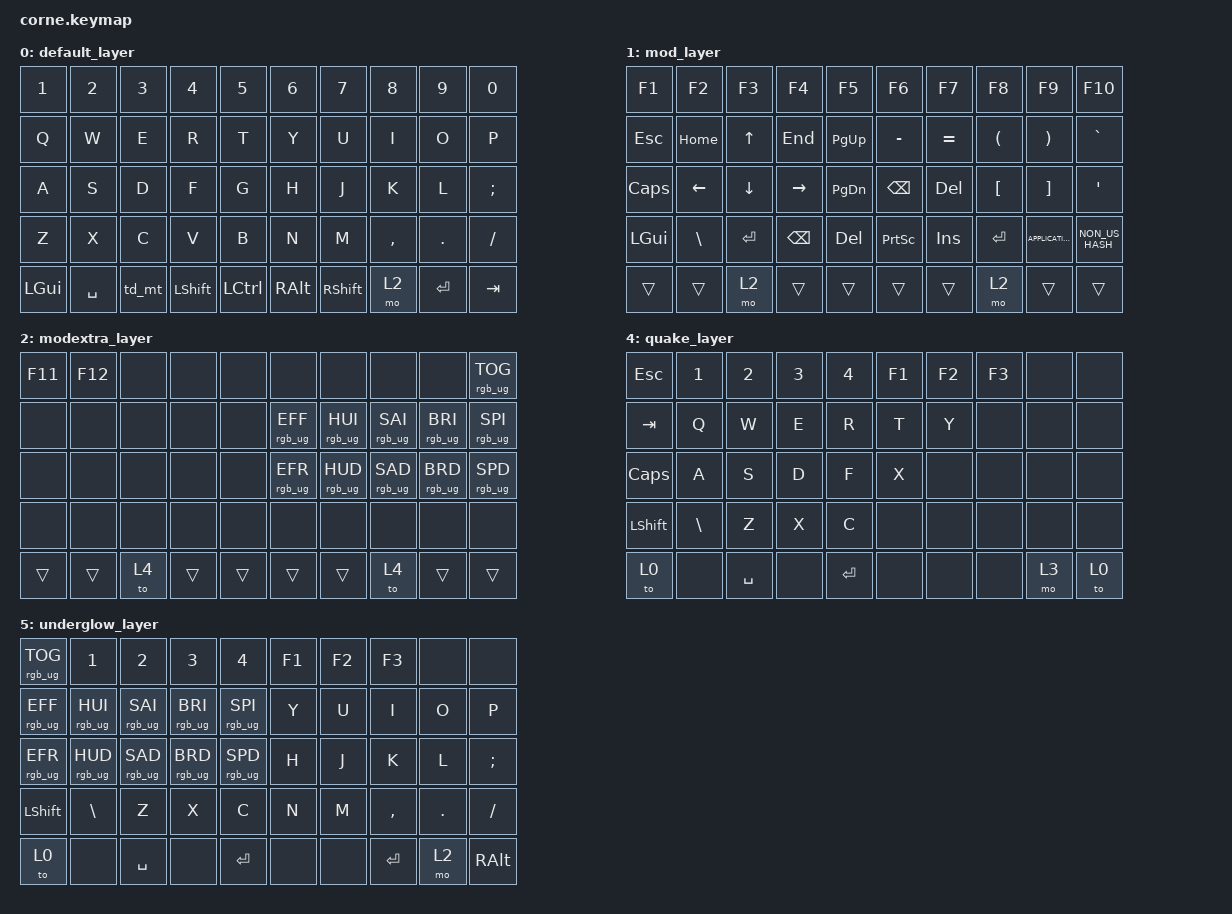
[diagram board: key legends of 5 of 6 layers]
/*
 * Copyright (c) 2020 The ZMK Contributors
 *
 * SPDX-License-Identifier: MIT
 */

#include <behaviors.dtsi>
#include <dt-bindings/zmk/keys.h>
#include <dt-bindings/zmk/bt.h>
#include <dt-bindings/zmk/rgb.h>

&led_strip {
    chain-length = <26>;
};


/ {
    behaviors {
        td_mt: tap_dance_mod_tap {
            compatible = "zmk,behavior-tap-dance";
            #binding-cells = <0>;
            tapping-term-ms = <200>;
            bindings = <&mo 1>, <&to 4>;
        };
    };

    keymap {
        compatible = "zmk,keymap";

        default_layer {
            bindings = <
                &td_mt
            >;
        };
    };
};

/ {
        keymap {
                compatible = "zmk,keymap";

                default_layer {
// -----------------------------------------------------------------------------------------
// |  TAB |  Q  |  W  |  E  |  R  |  T  |   |  Y  |  U   |  I  |  O  |  P  | BSPC |
// | CTRL |  A  |  S  |  D  |  F  |  G  |   |  H  |  J   |  K  |  L  |  ;  |  '   |
// | SHFT |  Z  |  X  |  C  |  V  |  B  |   |  N  |  M   |  ,  |  .  |  /  | ESC  |
//                    | GUI | LWR | SPC |   | ENT | RSE  | ALT |
                        bindings = <
   &kp N1 &kp N2 &kp N3 &kp N4 &kp   N5 &kp N6 &kp N7 &kp N8 &kp N9 &kp N0  
   &kp Q &kp W &kp E &kp R &kp T   &kp Y &kp U  &kp I     &kp O   &kp P    
   &kp A &kp S &kp D &kp F &kp G   &kp H &kp J  &kp K     &kp L   &kp SEMI 
   &kp Z &kp X &kp C &kp V &kp B   &kp N &kp M  &kp COMMA &kp DOT &kp FSLH
   &kp LGUI &kp SPACE &td_mt &kp LEFT_SHIFT &kp LEFT_CONTROL &kp RALT &kp RIGHT_SHIFT &mo 2 &kp ENTER &kp TAB
                        >;
                };
                mod_layer {
// -----------------------------------------------------------------------------------------
// |  TAB |  Q  |  W  |  E  |  R  |  T  |   |  Y  |  U   |  I  |  O  |  P  | BSPC |
// | CTRL |  A  |  S  |  D  |  F  |  G  |   |  H  |  J   |  K  |  L  |  ;  |  '   |
// | SHFT |  Z  |  X  |  C  |  V  |  B  |   |  N  |  M   |  ,  |  .  |  /  | ESC  |
//                    | GUI | LWR | SPC |   | ENT | RSE  | ALT |
                        bindings = <
   &kp F1 &kp F2 &kp F3 &kp F4 &kp   F5 &kp F6 &kp F7 &kp F8 &kp F9 &kp F10  
   &kp ESC &kp HOME &kp UP_ARROW &kp END &kp PAGE_UP &kp MINUS &kp EQUAL  &kp LEFT_PARENTHESIS &kp RIGHT_PARENTHESIS &kp GRAVE    
   &kp CAPSLOCK &kp LEFT_ARROW &kp DOWN_ARROW &kp RIGHT_ARROW &kp PAGE_DOWN &kp BACKSPACE &kp DELETE  &kp LEFT_BRACKET &kp RIGHT_BRACKET &kp SINGLE_QUOTE
   &kp LGUI &kp BACKSLASH &kp ENTER &kp BACKSPACE &kp DELETE   &kp PRINTSCREEN &kp INSERT  &kp ENTER &kp K_APPLICATION &kp NON_US_HASH
   &trans &trans &mo 2 &trans &trans &trans &trans &mo 2 &trans &trans
                        >;
                };

                modextra_layer {
// -----------------------------------------------------------------------------------------
// |  TAB |  Q  |  W  |  E  |  R  |  T  |   |  Y  |  U   |  I  |  O  |  P  | BSPC |
// | CTRL |  A  |  S  |  D  |  F  |  G  |   |  H  |  J   |  K  |  L  |  ;  |  '   |
// | SHFT |  Z  |  X  |  C  |  V  |  B  |   |  N  |  M   |  ,  |  .  |  /  | ESC  |
//                    | GUI | LWR | SPC |   | ENT | RSE  | ALT |
                        bindings = <
   &kp F11 &kp F12 &none &none &none &none &none &none &none &rgb_ug RGB_TOG  
   &none &none &none &none &none &rgb_ug RGB_EFF &rgb_ug RGB_HUI &rgb_ug RGB_SAI &rgb_ug RGB_BRI &rgb_ug RGB_SPI  
   &none &none &none &none &none &rgb_ug RGB_EFR &rgb_ug RGB_HUD &rgb_ug RGB_SAD &rgb_ug RGB_BRD &rgb_ug RGB_SPD
   &none &none &none &none &none &none &none  &none &none &none
   &trans &trans &to 4 &trans &trans &trans &trans &to 4 &trans &trans
                        >;
                };
                quickswitch_layer {
// -----------------------------------------------------------------------------------------
// |  TAB |  Q  |  W  |  E  |  R  |  T  |   |  Y  |  U   |  I  |  O  |  P  | BSPC |
// | CTRL |  A  |  S  |  D  |  F  |  G  |   |  H  |  J   |  K  |  L  |  ;  |  '   |
// | SHFT |  Z  |  X  |  C  |  V  |  B  |   |  N  |  M   |  ,  |  .  |  /  | ESC  |
//                    | GUI | LWR | SPC |   | ENT | RSE  | ALT |
                        bindings = <
   &kp F1 &kp F2 &kp F3 &kp F4 &kp   F5 &kp F6 &kp F7 &kp F8 &kp F9 &kp F10  
   &kp ESC &kp HOME &kp UP_ARROW &kp END &kp PAGE_UP &kp MINUS &kp EQUAL  &kp LEFT_PARENTHESIS &kp RIGHT_PARENTHESIS &kp GRAVE    
   &kp CAPSLOCK &kp LEFT_ARROW &kp DOWN_ARROW &kp RIGHT_ARROW &kp PAGE_DOWN &kp BACKSPACE &kp DELETE  &kp LEFT_BRACKET &kp RIGHT_BRACKET &kp SINGLE_QUOTE
   &kp LGUI &kp BACKSLASH &kp ENTER &kp BACKSPACE &kp DELETE   &kp PRINTSCREEN &kp INSERT  &kp ENTER &kp K_APPLICATION &kp NON_US_HASH
   &trans &trans &kp A &td_mt &kp LEFT_CONTROL &kp RET &mo 2 &kp RALT
                        >;
                };
                quake_layer {
// -----------------------------------------------------------------------------------------
// |  TAB |  Q  |  W  |  E  |  R  |  T  |   |  Y  |  U   |  I  |  O  |  P  | BSPC |
// | CTRL |  A  |  S  |  D  |  F  |  G  |   |  H  |  J   |  K  |  L  |  ;  |  '   |
// | SHFT |  Z  |  X  |  C  |  V  |  B  |   |  N  |  M   |  ,  |  .  |  /  | ESC  |
//                    | GUI | LWR | SPC |   | ENT | RSE  | ALT |
                        bindings = <
   &kp ESC &kp N1 &kp N2 &kp N3 &kp N4 &kp F1 &kp F2 &kp F3 &none  &none
   &kp TAB &kp Q &kp W &kp E &kp R &kp T &kp Y  &none &none &none   
   &kp CAPSLOCK &kp A &kp S &kp D &kp F &kp X &none &none &none &none
   &kp LEFT_SHIFT  &kp BSLH &kp Z &kp X &kp C &none &none &none &none &none
   &to 0 &none &kp SPACE &none &kp ENTER &none &none &none &mo 3 &to 0
                        >;
                };
                underglow_layer {
// -----------------------------------------------------------------------------------------
// |  TAB |  Q  |  W  |  E  |  R  |  T  |   |  Y  |  U   |  I  |  O  |  P  | BSPC |
// | CTRL |  A  |  S  |  D  |  F  |  G  |   |  H  |  J   |  K  |  L  |  ;  |  '   |
// | SHFT |  Z  |  X  |  C  |  V  |  B  |   |  N  |  M   |  ,  |  .  |  /  | ESC  |
//                    | GUI | LWR | SPC |   | ENT | RSE  | ALT |
                        bindings = <
   &rgb_ug RGB_TOG &kp N1 &kp N2 &kp N3 &kp N4 &kp F1 &kp F2 &kp F3 &none  &none
   &rgb_ug RGB_EFF &rgb_ug RGB_HUI &rgb_ug RGB_SAI &rgb_ug RGB_BRI &rgb_ug RGB_SPI &kp Y &kp U  &kp I     &kp O   &kp P    
   &rgb_ug RGB_EFR &rgb_ug RGB_HUD &rgb_ug RGB_SAD &rgb_ug RGB_BRD &rgb_ug RGB_SPD  &kp H &kp J  &kp K     &kp L   &kp SEMI 
   &kp LEFT_SHIFT  &kp BSLH &kp Z &kp X &kp C &kp N &kp M  &kp COMMA &kp DOT &kp FSLH
   &to 0 &none &kp SPACE &none &kp ENTER &none &none &kp RET &mo 2 &kp RALT
                        >;
                };


        };
};
